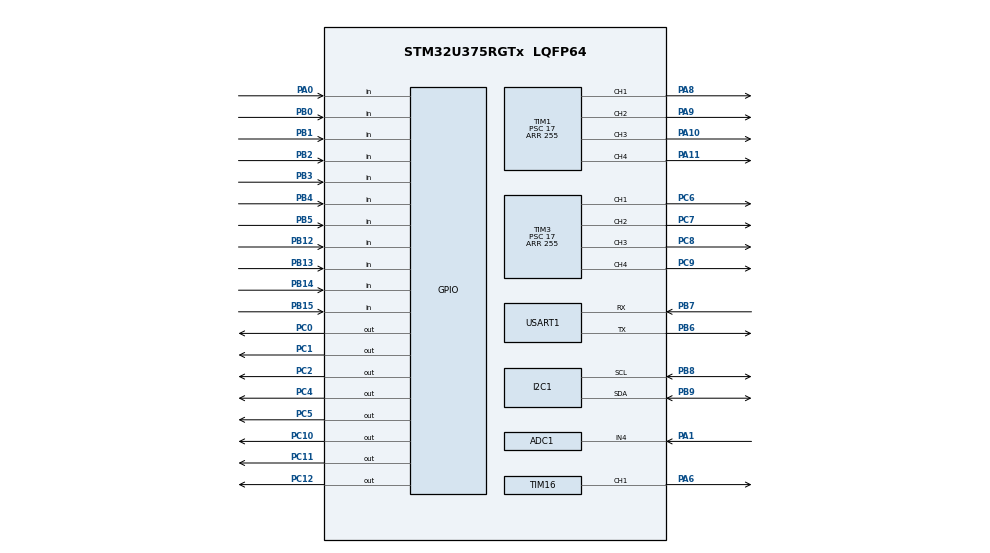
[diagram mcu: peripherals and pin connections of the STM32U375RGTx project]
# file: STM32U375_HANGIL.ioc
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ADC1.Channel-2\#ChannelRegularConversion=ADC_CHANNEL_4
ADC1.MonitoredBy-2\#ChannelRegularConversion=__NULL
ADC1.NbrOfConversionFlag=1
ADC1.OffsetNumber-2\#ChannelRegularConversion=ADC_OFFSET_NONE
ADC1.Rank-2\#ChannelRegularConversion=1
ADC1.SamplingTime-2\#ChannelRegularConversion=ADC_SAMPLETIME_1CYCLE_5
ADC1.master=1
CORTEX_M33_NS.userName=CORTEX_M33
I2C1.Timing=0x10B0DCFB
Mcu.Family=STM32U3
Mcu.Name=STM32U375RGTx
Mcu.Package=LQFP64
NVIC.PriorityGroup=NVIC_PRIORITYGROUP_4
NVIC.TIM2_IRQn=true\:0\:0\:false\:false\:true\:true\:true\:true
NVIC.TIM4_IRQn=true\:0\:0\:false\:false\:true\:true\:true\:true
NVIC.TIM6_IRQn=true\:0\:0\:false\:false\:true\:true\:true\:true
PA0.Signal=GPIO_Input
PA1.Mode=IN4-Single-Ended
PA1.Signal=ADC1_IN4
PA10.Signal=S_TIM1_CH3
PA11.Signal=S_TIM1_CH4
PA13\ (JTMS/SWDIO).Mode=Serial_Wire
PA13\ (JTMS/SWDIO).Signal=DEBUG_JTMS-SWDIO
PA14\ (JTCK/SWCLK).Mode=Serial_Wire
PA14\ (JTCK/SWCLK).Signal=DEBUG_JTCK-SWCLK
PA6.Signal=S_TIM16_CH1
PA8.Signal=S_TIM1_CH1
PA9.Signal=S_TIM1_CH2
PB0.Signal=GPIO_Input
PB1.Signal=GPIO_Input
PB12.Signal=GPIO_Input
PB13.Signal=GPIO_Input
PB14.Signal=GPIO_Input
PB15.Signal=GPIO_Input
PB2.Signal=GPIO_Input
PB3\ (JTDO/TRACESWO).Signal=GPIO_Input
PB4\ (NJTRST).Signal=GPIO_Input
PB5.Signal=GPIO_Input
PB6.Mode=Asynchronous
PB6.Signal=USART1_TX
PB7.Mode=Asynchronous
PB7.Signal=USART1_RX
PB8.Mode=I2C
PB8.Signal=I2C1_SCL
PB9.Mode=I2C
PB9.Signal=I2C1_SDA
PC0.Signal=GPIO_Output
PC1.Signal=GPIO_Output
PC10.Signal=GPIO_Output
PC11.Signal=GPIO_Output
PC12.Signal=GPIO_Output
PC2.Signal=GPIO_Output
PC4.Signal=GPIO_Output
PC5.Signal=GPIO_Output
PC6.Signal=S_TIM3_CH1
PC7.Signal=S_TIM3_CH2
PC8.Signal=S_TIM3_CH3
PC9.Signal=S_TIM3_CH4
PH0-OSC_IN\ (PH0).Mode=HSE-External-Oscillator
PH0-OSC_IN\ (PH0).Signal=RCC_OSC_IN
PH1-OSC_OUT\ (PH1).Mode=HSE-External-Oscillator
PH1-OSC_OUT\ (PH1).Signal=RCC_OSC_OUT
ProjectManager.HeapSize=0x200
ProjectManager.StackSize=0x400
ProjectManager.TargetToolchain=STM32CubeIDE
RCC.ADCFreq_Value=96000000
RCC.AHBFreq_Value=96000000
RCC.APB1Freq_Value=96000000
RCC.APB1TimFreq_Value=96000000
RCC.APB2Freq_Value=96000000
RCC.APB2TimFreq_Value=96000000
RCC.APB3Freq_Value=96000000
RCC.CortexFreq_Value=12000000
RCC.HCLKFreq_Value=96000000
RCC.HSE_VALUE=32000000
RCC.HSI48_VALUE=48000000
RCC.HSI_VALUE=16000000
RCC.LSE_VALUE=32768
RCC.LSIDIV_VALUE=32000
RCC.MSISDIV=RCC_MSI_DIV1
RCC.SYSCLKFreq_VALUE=96000000
RCC.USBFreq_Value=96000000
SH.S_TIM16_CH1.0=TIM16_CH1,PWM Generation1 CH1
SH.S_TIM1_CH1.0=TIM1_CH1,PWM Generation1 CH1
SH.S_TIM1_CH2.0=TIM1_CH2,PWM Generation2 CH2
SH.S_TIM1_CH3.0=TIM1_CH3,PWM Generation3 CH3
SH.S_TIM1_CH4.0=TIM1_CH4,PWM Generation4 CH4
SH.S_TIM3_CH1.0=TIM3_CH1,PWM Generation1 CH1
SH.S_TIM3_CH2.0=TIM3_CH2,PWM Generation2 CH2
SH.S_TIM3_CH3.0=TIM3_CH3,PWM Generation3 CH3
SH.S_TIM3_CH4.0=TIM3_CH4,PWM Generation4 CH4
TIM1.Channel-PWM\ Generation1\ CH1=TIM_CHANNEL_1
TIM1.Channel-PWM\ Generation2\ CH2=TIM_CHANNEL_2
TIM1.Channel-PWM\ Generation3\ CH3=TIM_CHANNEL_3
TIM1.Channel-PWM\ Generation4\ CH4=TIM_CHANNEL_4
TIM1.PeriodNoDither=255
TIM1.Prescaler=17
TIM16.Channel=TIM_CHANNEL_1
TIM16.Prescaler=95
TIM2.Prescaler=95
TIM3.Channel-PWM\ Generation1\ CH1=TIM_CHANNEL_1
TIM3.Channel-PWM\ Generation2\ CH2=TIM_CHANNEL_2
TIM3.Channel-PWM\ Generation3\ CH3=TIM_CHANNEL_3
TIM3.Channel-PWM\ Generation4\ CH4=TIM_CHANNEL_4
TIM3.PeriodNoDither=255
TIM3.Prescaler=17
TIM4.PeriodNoDither=29
TIM4.Prescaler=95
TIM6.PeriodNoDither=999
TIM6.Prescaler=95
USART1.VirtualMode-Asynchronous=VM_ASYNC
VP_MEMORYMAP_VS_MEMORYMAP.Mode=CurAppReg
VP_PWR_VS_DBSignals.Mode=DisableDeadBatterySignals
VP_PWR_VS_LPOM.Mode=PowerOptimisation
VP_PWR_VS_SECSignals.Mode=Security/Privilege
VP_TIM16_VS_ClockSourceINT.Mode=Enable_Timer
VP_TIM2_VS_ClockSourceINT.Mode=Internal
VP_TIM4_VS_ClockSourceINT.Mode=Internal
VP_TIM6_VS_ClockSourceINT.Mode=Enable_Timer
board=custom

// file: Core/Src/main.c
/* USER CODE BEGIN Header */
/**
  ******************************************************************************
  * @file           : main.c
  * @brief          : Main program body
  ******************************************************************************
  * @attention
  *
  * Copyright (c) 2025 STMicroelectronics.
  * All rights reserved.
  *
  * This software is licensed under terms that can be found in the LICENSE file
  * in the root directory of this software component.
  * If no LICENSE file comes with this software, it is provided AS-IS.
  *
  ******************************************************************************
  */
/* USER CODE END Header */
#include "main.h"

/* USER CODE BEGIN Includes */
#include "ap.h"
/* USER CODE END Includes */

ADC_HandleTypeDef hadc1;

I2C_HandleTypeDef hi2c1;

TIM_HandleTypeDef htim1;
TIM_HandleTypeDef htim2;
TIM_HandleTypeDef htim3;
TIM_HandleTypeDef htim4;
TIM_HandleTypeDef htim6;
TIM_HandleTypeDef htim16;

UART_HandleTypeDef huart1;

void SystemClock_Config(void);
static void MX_GPIO_Init(void);
static void MX_I2C1_Init(void);
static void MX_TIM4_Init(void);
static void MX_TIM6_Init(void);
static void MX_USART1_UART_Init(void);
static void MX_ADC1_Init(void);
static void MX_TIM16_Init(void);
static void MX_TIM2_Init(void);
static void MX_TIM1_Init(void);
static void MX_TIM3_Init(void);

int main(void)
{

  /* MCU Configuration--------------------------------------------------------*/

  /* Reset of all peripherals, Initializes the Flash interface and the Systick. */
  HAL_Init();

  /* Configure the system clock */
  SystemClock_Config();

  /* USER CODE BEGIN SysInit */
  // ★ 가장 먼저: 켤 때 1초 길게 눌림 검증
  lp_stby_boot_gate();

  /* USER CODE END SysInit */

  /* Initialize all configured peripherals */
  MX_GPIO_Init();
  MX_I2C1_Init();
  MX_TIM4_Init();
  MX_TIM6_Init();
  MX_USART1_UART_Init();
  MX_ADC1_Init();
  MX_TIM16_Init();
  MX_TIM2_Init();
  MX_TIM1_Init();
  MX_TIM3_Init();
  /* USER CODE BEGIN 2 */
  ap_init();
  ap_main();
  /* USER CODE END 2 */

  /* Infinite loop */
  while (1)
  {

  }
}

void SystemClock_Config(void)
{
  RCC_OscInitTypeDef RCC_OscInitStruct = {0};
  RCC_ClkInitTypeDef RCC_ClkInitStruct = {0};

  /** Enable Epod Booster
  */
  if (HAL_RCCEx_EpodBoosterClkConfig(RCC_EPODBOOSTER_SOURCE_MSIS, RCC_EPODBOOSTER_DIV1) != HAL_OK)
  {
    Error_Handler();
  }
  if (HAL_PWREx_EnableEpodBooster() != HAL_OK)
  {
    Error_Handler();
  }

  /** Configure the main internal regulator output voltage
  */
  if (HAL_PWREx_ControlVoltageScaling(PWR_REGULATOR_VOLTAGE_SCALE1) != HAL_OK)
  {
    Error_Handler();
  }

  /** Set Flash latency before increasing MSIS
  */
  __HAL_FLASH_SET_LATENCY(FLASH_LATENCY_2);

  /** Initializes the CPU, AHB and APB buses clocks
  */
  RCC_OscInitStruct.OscillatorType = RCC_OSCILLATORTYPE_MSIS;
  RCC_OscInitStruct.MSISState = RCC_MSI_ON;
  RCC_OscInitStruct.MSISSource = RCC_MSI_RC0;
  RCC_OscInitStruct.MSISDiv = RCC_MSI_DIV1;
  if (HAL_RCC_OscConfig(&RCC_OscInitStruct) != HAL_OK)
  {
    Error_Handler();
  }

  /** Initializes the CPU, AHB and APB buses clocks
  */
  RCC_ClkInitStruct.ClockType = RCC_CLOCKTYPE_HCLK|RCC_CLOCKTYPE_SYSCLK
                              |RCC_CLOCKTYPE_PCLK1|RCC_CLOCKTYPE_PCLK2
                              |RCC_CLOCKTYPE_PCLK3;
  RCC_ClkInitStruct.SYSCLKSource = RCC_SYSCLKSOURCE_MSIS;
  RCC_ClkInitStruct.AHBCLKDivider = RCC_SYSCLK_DIV1;
  RCC_ClkInitStruct.APB1CLKDivider = RCC_HCLK_DIV1;
  RCC_ClkInitStruct.APB2CLKDivider = RCC_HCLK_DIV1;
  RCC_ClkInitStruct.APB3CLKDivider = RCC_HCLK_DIV1;

  if (HAL_RCC_ClockConfig(&RCC_ClkInitStruct, FLASH_LATENCY_2) != HAL_OK)
  {
    Error_Handler();
  }
}

static void MX_ADC1_Init(void)
{

  ADC_ChannelConfTypeDef sConfig = {0};

  /** Common config
  */
  hadc1.Instance = ADC1;
  hadc1.Init.Resolution = ADC_RESOLUTION_12B;
  hadc1.Init.GainCompensation = 0;
  hadc1.Init.ScanConvMode = ADC_SCAN_DISABLE;
  hadc1.Init.EOCSelection = ADC_EOC_SINGLE_CONV;
  hadc1.Init.LowPowerAutoWait = DISABLE;
  hadc1.Init.ContinuousConvMode = DISABLE;
  hadc1.Init.NbrOfConversion = 1;
  hadc1.Init.DiscontinuousConvMode = DISABLE;
  hadc1.Init.ExternalTrigConv = ADC_SOFTWARE_START;
  hadc1.Init.ExternalTrigConvEdge = ADC_EXTERNALTRIGCONVEDGE_NONE;
  hadc1.Init.Overrun = ADC_OVR_DATA_PRESERVED;
  hadc1.Init.LeftBitShift = ADC_LEFTBITSHIFT_NONE;
  hadc1.Init.ConversionDataManagement = ADC_CONVERSIONDATA_DR;
  hadc1.Init.OversamplingMode = DISABLE;
  if (HAL_ADC_Init(&hadc1) != HAL_OK)
  {
    Error_Handler();
  }

  /** Configure Regular Channel
  */
  sConfig.Channel = ADC_CHANNEL_4;
  sConfig.Rank = ADC_REGULAR_RANK_1;
  sConfig.SamplingTime = ADC_SAMPLETIME_1CYCLE_5;
  sConfig.OffsetNumber = ADC_OFFSET_NONE;
  sConfig.Offset = 0;
  if (HAL_ADC_ConfigChannel(&hadc1, &sConfig) != HAL_OK)
  {
    Error_Handler();
  }

}

static void MX_I2C1_Init(void)
{

  hi2c1.Instance = I2C1;
  hi2c1.Init.Timing = 0x10B0DCFB;
  hi2c1.Init.OwnAddress1 = 0;
  hi2c1.Init.AddressingMode = I2C_ADDRESSINGMODE_7BIT;
  hi2c1.Init.DualAddressMode = I2C_DUALADDRESS_DISABLE;
  hi2c1.Init.OwnAddress2 = 0;
  hi2c1.Init.OwnAddress2Masks = I2C_OA2_NOMASK;
  hi2c1.Init.GeneralCallMode = I2C_GENERALCALL_DISABLE;
  hi2c1.Init.NoStretchMode = I2C_NOSTRETCH_DISABLE;
  if (HAL_I2C_Init(&hi2c1) != HAL_OK)
  {
    Error_Handler();
  }

  /** Configure Analogue filter
  */
  if (HAL_I2CEx_ConfigAnalogFilter(&hi2c1, I2C_ANALOGFILTER_ENABLE) != HAL_OK)
  {
    Error_Handler();
  }

  /** Configure Digital filter
  */
  if (HAL_I2CEx_ConfigDigitalFilter(&hi2c1, 0) != HAL_OK)
  {
    Error_Handler();
  }

}

static void MX_TIM1_Init(void)
{

  TIM_MasterConfigTypeDef sMasterConfig = {0};
  TIM_OC_InitTypeDef sConfigOC = {0};
  TIM_BreakDeadTimeConfigTypeDef sBreakDeadTimeConfig = {0};

  htim1.Instance = TIM1;
  htim1.Init.Prescaler = 17;
  htim1.Init.CounterMode = TIM_COUNTERMODE_UP;
  htim1.Init.Period = 255;
  htim1.Init.ClockDivision = TIM_CLOCKDIVISION_DIV1;
  htim1.Init.RepetitionCounter = 0;
  htim1.Init.AutoReloadPreload = TIM_AUTORELOAD_PRELOAD_DISABLE;
  if (HAL_TIM_PWM_Init(&htim1) != HAL_OK)
  {
    Error_Handler();
  }
  sMasterConfig.MasterOutputTrigger = TIM_TRGO_RESET;
  sMasterConfig.MasterOutputTrigger2 = TIM_TRGO2_RESET;
  sMasterConfig.MasterSlaveMode = TIM_MASTERSLAVEMODE_DISABLE;
  if (HAL_TIMEx_MasterConfigSynchronization(&htim1, &sMasterConfig) != HAL_OK)
  {
    Error_Handler();
  }
  sConfigOC.OCMode = TIM_OCMODE_PWM1;
  sConfigOC.Pulse = 0;
  sConfigOC.OCPolarity = TIM_OCPOLARITY_HIGH;
  sConfigOC.OCNPolarity = TIM_OCNPOLARITY_HIGH;
  sConfigOC.OCFastMode = TIM_OCFAST_DISABLE;
  sConfigOC.OCIdleState = TIM_OCIDLESTATE_RESET;
  sConfigOC.OCNIdleState = TIM_OCNIDLESTATE_RESET;
  if (HAL_TIM_PWM_ConfigChannel(&htim1, &sConfigOC, TIM_CHANNEL_1) != HAL_OK)
  {
    Error_Handler();
  }
  if (HAL_TIM_PWM_ConfigChannel(&htim1, &sConfigOC, TIM_CHANNEL_2) != HAL_OK)
  {
    Error_Handler();
  }
  if (HAL_TIM_PWM_ConfigChannel(&htim1, &sConfigOC, TIM_CHANNEL_3) != HAL_OK)
  {
    Error_Handler();
  }
  if (HAL_TIM_PWM_ConfigChannel(&htim1, &sConfigOC, TIM_CHANNEL_4) != HAL_OK)
  {
    Error_Handler();
  }
  sBreakDeadTimeConfig.OffStateRunMode = TIM_OSSR_DISABLE;
  sBreakDeadTimeConfig.OffStateIDLEMode = TIM_OSSI_DISABLE;
  sBreakDeadTimeConfig.LockLevel = TIM_LOCKLEVEL_OFF;
  sBreakDeadTimeConfig.DeadTime = 0;
  sBreakDeadTimeConfig.BreakState = TIM_BREAK_DISABLE;
  sBreakDeadTimeConfig.BreakPolarity = TIM_BREAKPOLARITY_HIGH;
  sBreakDeadTimeConfig.BreakFilter = 0;
  sBreakDeadTimeConfig.BreakAFMode = TIM_BREAK_AFMODE_INPUT;
  sBreakDeadTimeConfig.Break2State = TIM_BREAK2_DISABLE;
  sBreakDeadTimeConfig.Break2Polarity = TIM_BREAK2POLARITY_HIGH;
  sBreakDeadTimeConfig.Break2Filter = 0;
  sBreakDeadTimeConfig.Break2AFMode = TIM_BREAK_AFMODE_INPUT;
  sBreakDeadTimeConfig.AutomaticOutput = TIM_AUTOMATICOUTPUT_DISABLE;
  if (HAL_TIMEx_ConfigBreakDeadTime(&htim1, &sBreakDeadTimeConfig) != HAL_OK)
  {
    Error_Handler();
  }
  HAL_TIM_MspPostInit(&htim1);

}

static void MX_TIM2_Init(void)
{

  TIM_ClockConfigTypeDef sClockSourceConfig = {0};
  TIM_MasterConfigTypeDef sMasterConfig = {0};

  htim2.Instance = TIM2;
  htim2.Init.Prescaler = 95;
  htim2.Init.CounterMode = TIM_COUNTERMODE_UP;
  htim2.Init.Period = 4294967295;
  htim2.Init.ClockDivision = TIM_CLOCKDIVISION_DIV1;
  htim2.Init.AutoReloadPreload = TIM_AUTORELOAD_PRELOAD_DISABLE;
  if (HAL_TIM_Base_Init(&htim2) != HAL_OK)
  {
    Error_Handler();
  }
  sClockSourceConfig.ClockSource = TIM_CLOCKSOURCE_INTERNAL;
  if (HAL_TIM_ConfigClockSource(&htim2, &sClockSourceConfig) != HAL_OK)
  {
    Error_Handler();
  }
  sMasterConfig.MasterOutputTrigger = TIM_TRGO_RESET;
  sMasterConfig.MasterSlaveMode = TIM_MASTERSLAVEMODE_DISABLE;
  if (HAL_TIMEx_MasterConfigSynchronization(&htim2, &sMasterConfig) != HAL_OK)
  {
    Error_Handler();
  }

}

static void MX_TIM3_Init(void)
{

  TIM_MasterConfigTypeDef sMasterConfig = {0};
  TIM_OC_InitTypeDef sConfigOC = {0};

  htim3.Instance = TIM3;
  htim3.Init.Prescaler = 17;
  htim3.Init.CounterMode = TIM_COUNTERMODE_UP;
  htim3.Init.Period = 255;
  htim3.Init.ClockDivision = TIM_CLOCKDIVISION_DIV1;
  htim3.Init.AutoReloadPreload = TIM_AUTORELOAD_PRELOAD_DISABLE;
  if (HAL_TIM_PWM_Init(&htim3) != HAL_OK)
  {
    Error_Handler();
  }
  sMasterConfig.MasterOutputTrigger = TIM_TRGO_RESET;
  sMasterConfig.MasterSlaveMode = TIM_MASTERSLAVEMODE_DISABLE;
  if (HAL_TIMEx_MasterConfigSynchronization(&htim3, &sMasterConfig) != HAL_OK)
  {
    Error_Handler();
  }
  sConfigOC.OCMode = TIM_OCMODE_PWM1;
  sConfigOC.Pulse = 0;
  sConfigOC.OCPolarity = TIM_OCPOLARITY_HIGH;
  sConfigOC.OCFastMode = TIM_OCFAST_DISABLE;
  if (HAL_TIM_PWM_ConfigChannel(&htim3, &sConfigOC, TIM_CHANNEL_1) != HAL_OK)
  {
    Error_Handler();
  }
  if (HAL_TIM_PWM_ConfigChannel(&htim3, &sConfigOC, TIM_CHANNEL_2) != HAL_OK)
  {
    Error_Handler();
  }
  if (HAL_TIM_PWM_ConfigChannel(&htim3, &sConfigOC, TIM_CHANNEL_3) != HAL_OK)
  {
    Error_Handler();
  }
  if (HAL_TIM_PWM_ConfigChannel(&htim3, &sConfigOC, TIM_CHANNEL_4) != HAL_OK)
  {
    Error_Handler();
  }
  HAL_TIM_MspPostInit(&htim3);

}

static void MX_TIM4_Init(void)
{

  TIM_ClockConfigTypeDef sClockSourceConfig = {0};
  TIM_MasterConfigTypeDef sMasterConfig = {0};

  htim4.Instance = TIM4;
  htim4.Init.Prescaler = 95;
  htim4.Init.CounterMode = TIM_COUNTERMODE_UP;
  htim4.Init.Period = 29;
  htim4.Init.ClockDivision = TIM_CLOCKDIVISION_DIV1;
  htim4.Init.AutoReloadPreload = TIM_AUTORELOAD_PRELOAD_DISABLE;
  if (HAL_TIM_Base_Init(&htim4) != HAL_OK)
  {
    Error_Handler();
  }
  sClockSourceConfig.ClockSource = TIM_CLOCKSOURCE_INTERNAL;
  if (HAL_TIM_ConfigClockSource(&htim4, &sClockSourceConfig) != HAL_OK)
  {
    Error_Handler();
  }
  sMasterConfig.MasterOutputTrigger = TIM_TRGO_RESET;
  sMasterConfig.MasterSlaveMode = TIM_MASTERSLAVEMODE_DISABLE;
  if (HAL_TIMEx_MasterConfigSynchronization(&htim4, &sMasterConfig) != HAL_OK)
  {
    Error_Handler();
  }

}

static void MX_TIM6_Init(void)
{

  TIM_MasterConfigTypeDef sMasterConfig = {0};

  htim6.Instance = TIM6;
  htim6.Init.Prescaler = 95;
  htim6.Init.CounterMode = TIM_COUNTERMODE_UP;
  htim6.Init.Period = 999;
  htim6.Init.AutoReloadPreload = TIM_AUTORELOAD_PRELOAD_DISABLE;
  if (HAL_TIM_Base_Init(&htim6) != HAL_OK)
  {
    Error_Handler();
  }
  sMasterConfig.MasterOutputTrigger = TIM_TRGO_RESET;
  sMasterConfig.MasterSlaveMode = TIM_MASTERSLAVEMODE_DISABLE;
  if (HAL_TIMEx_MasterConfigSynchronization(&htim6, &sMasterConfig) != HAL_OK)
  {
    Error_Handler();
  }

}

static void MX_TIM16_Init(void)
{

  TIM_OC_InitTypeDef sConfigOC = {0};
  TIM_BreakDeadTimeConfigTypeDef sBreakDeadTimeConfig = {0};

  htim16.Instance = TIM16;
  htim16.Init.Prescaler = 95;
  htim16.Init.CounterMode = TIM_COUNTERMODE_UP;
  htim16.Init.Period = 65535;
  htim16.Init.ClockDivision = TIM_CLOCKDIVISION_DIV1;
  htim16.Init.RepetitionCounter = 0;
  htim16.Init.AutoReloadPreload = TIM_AUTORELOAD_PRELOAD_DISABLE;
  if (HAL_TIM_Base_Init(&htim16) != HAL_OK)
  {
    Error_Handler();
  }
  if (HAL_TIM_PWM_Init(&htim16) != HAL_OK)
  {
    Error_Handler();
  }
  sConfigOC.OCMode = TIM_OCMODE_PWM1;
  sConfigOC.Pulse = 0;
  sConfigOC.OCPolarity = TIM_OCPOLARITY_HIGH;
  sConfigOC.OCNPolarity = TIM_OCNPOLARITY_HIGH;
  sConfigOC.OCFastMode = TIM_OCFAST_DISABLE;
  sConfigOC.OCIdleState = TIM_OCIDLESTATE_RESET;
  sConfigOC.OCNIdleState = TIM_OCNIDLESTATE_RESET;
  if (HAL_TIM_PWM_ConfigChannel(&htim16, &sConfigOC, TIM_CHANNEL_1) != HAL_OK)
  {
    Error_Handler();
  }
  sBreakDeadTimeConfig.OffStateRunMode = TIM_OSSR_DISABLE;
  sBreakDeadTimeConfig.OffStateIDLEMode = TIM_OSSI_DISABLE;
  sBreakDeadTimeConfig.LockLevel = TIM_LOCKLEVEL_OFF;
  sBreakDeadTimeConfig.DeadTime = 0;
  sBreakDeadTimeConfig.BreakState = TIM_BREAK_DISABLE;
  sBreakDeadTimeConfig.BreakPolarity = TIM_BREAKPOLARITY_HIGH;
  sBreakDeadTimeConfig.BreakFilter = 0;
  sBreakDeadTimeConfig.AutomaticOutput = TIM_AUTOMATICOUTPUT_DISABLE;
  if (HAL_TIMEx_ConfigBreakDeadTime(&htim16, &sBreakDeadTimeConfig) != HAL_OK)
  {
    Error_Handler();
  }
  HAL_TIM_MspPostInit(&htim16);

}

static void MX_USART1_UART_Init(void)
{

  huart1.Instance = USART1;
  huart1.Init.BaudRate = 115200;
  huart1.Init.WordLength = UART_WORDLENGTH_8B;
  huart1.Init.StopBits = UART_STOPBITS_1;
  huart1.Init.Parity = UART_PARITY_NONE;
  huart1.Init.Mode = UART_MODE_TX_RX;
  huart1.Init.HwFlowCtl = UART_HWCONTROL_NONE;
  huart1.Init.OverSampling = UART_OVERSAMPLING_16;
  huart1.Init.OneBitSampling = UART_ONE_BIT_SAMPLE_DISABLE;
  huart1.Init.ClockPrescaler = UART_PRESCALER_DIV1;
  huart1.AdvancedInit.AdvFeatureInit = UART_ADVFEATURE_NO_INIT;
  if (HAL_UART_Init(&huart1) != HAL_OK)
  {
    Error_Handler();
  }
  if (HAL_UARTEx_SetTxFifoThreshold(&huart1, UART_TXFIFO_THRESHOLD_1_8) != HAL_OK)
  {
    Error_Handler();
  }
  if (HAL_UARTEx_SetRxFifoThreshold(&huart1, UART_RXFIFO_THRESHOLD_1_8) != HAL_OK)
  {
    Error_Handler();
  }
  if (HAL_UARTEx_DisableFifoMode(&huart1) != HAL_OK)
  {
    Error_Handler();
  }

}

static void MX_GPIO_Init(void)
{
  GPIO_InitTypeDef GPIO_InitStruct = {0};

  /* GPIO Ports Clock Enable */
  __HAL_RCC_GPIOH_CLK_ENABLE();
  __HAL_RCC_GPIOC_CLK_ENABLE();
  __HAL_RCC_GPIOA_CLK_ENABLE();
  __HAL_RCC_GPIOB_CLK_ENABLE();

  /*Configure GPIO pin Output Level */
  HAL_GPIO_WritePin(GPIOC, GPIO_PIN_0|GPIO_PIN_1|GPIO_PIN_2|GPIO_PIN_4
                          |GPIO_PIN_5|GPIO_PIN_10|GPIO_PIN_11|GPIO_PIN_12, GPIO_PIN_RESET);

  /*Configure GPIO pins : PC0 PC1 PC2 PC4
                           PC5 PC10 PC11 PC12 */
  GPIO_InitStruct.Pin = GPIO_PIN_0|GPIO_PIN_1|GPIO_PIN_2|GPIO_PIN_4
                          |GPIO_PIN_5|GPIO_PIN_10|GPIO_PIN_11|GPIO_PIN_12;
  GPIO_InitStruct.Mode = GPIO_MODE_OUTPUT_PP;
  GPIO_InitStruct.Pull = GPIO_NOPULL;
  GPIO_InitStruct.Speed = GPIO_SPEED_FREQ_LOW;
  HAL_GPIO_Init(GPIOC, &GPIO_InitStruct);

  /*Configure GPIO pin : PA0 */
  GPIO_InitStruct.Pin = GPIO_PIN_0;
  GPIO_InitStruct.Mode = GPIO_MODE_INPUT;
  GPIO_InitStruct.Pull = GPIO_NOPULL;
  HAL_GPIO_Init(GPIOA, &GPIO_InitStruct);

  /*Configure GPIO pins : PB0 PB1 PB2 PB12
                           PB13 PB14 PB15 PB3
                           PB4 PB5 */
  GPIO_InitStruct.Pin = GPIO_PIN_0|GPIO_PIN_1|GPIO_PIN_2|GPIO_PIN_12
                          |GPIO_PIN_13|GPIO_PIN_14|GPIO_PIN_15|GPIO_PIN_3
                          |GPIO_PIN_4|GPIO_PIN_5;
  GPIO_InitStruct.Mode = GPIO_MODE_INPUT;
  GPIO_InitStruct.Pull = GPIO_NOPULL;
  HAL_GPIO_Init(GPIOB, &GPIO_InitStruct);

}

void Error_Handler(void)
{
  __disable_irq();
  while (1)
  {
  }
}
